AUTOSAR XML (schema 00046)
package /ComponentTypes
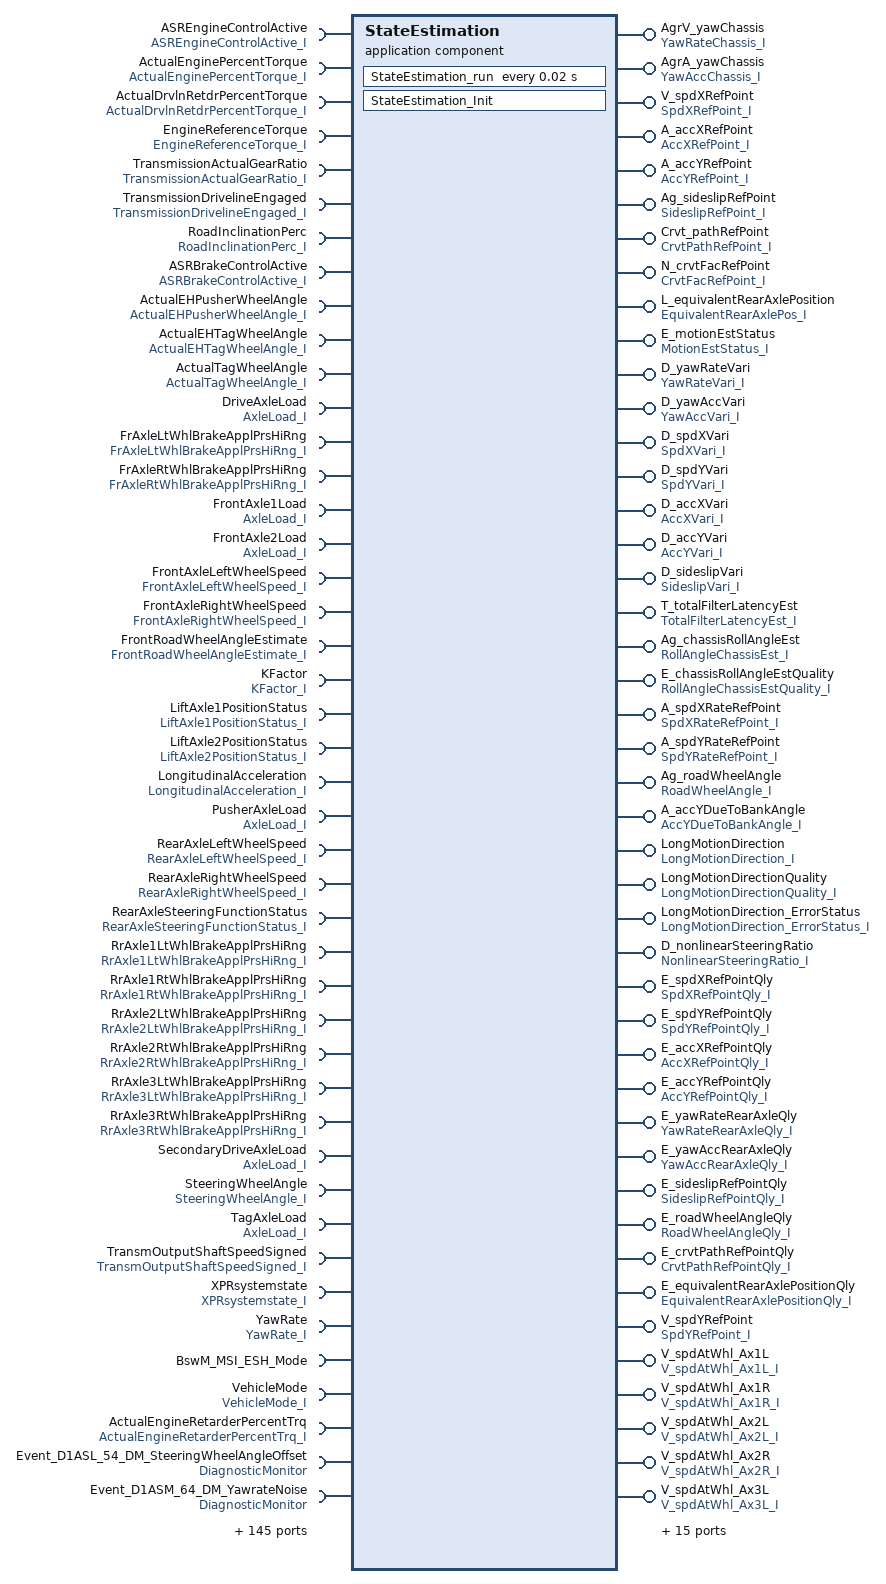
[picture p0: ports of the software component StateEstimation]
  application sw component type StateEstimation
    6 x require port:
      ASREngineControlActive: nonqueued-receiver-com-spec{data-element=ASREngineControlActive, alive-timeout=30, filter=data-filter-type=ALWAYS, init-value=constant-reference=C_ASREngineControlActive_IV}, required-interface=ASREngineControlActive_I
      ActualEnginePercentTorque: nonqueued-receiver-com-spec{data-element=ActualEnginePercentTorque, alive-timeout=30, init-value=constant-reference=C_ActualEnginePercentTorque_IV}, required-interface=ActualEnginePercentTorque_I
      ActualDrvlnRetdrPercentTorque: nonqueued-receiver-com-spec{data-element=ActualDrvlnRetdrPercentTorque, alive-timeout=30, init-value=constant-reference=C_ActualDrvlnRetdrPercentTorque_IV}, required-interface=ActualDrvlnRetdrPercentTorque_I
      EngineReferenceTorque: queued-receiver-com-spec{data-element=EngineReferenceTorque, queue-length=1}, required-interface=EngineReferenceTorque_I
      TransmissionActualGearRatio: nonqueued-receiver-com-spec{data-element=TransmissionActualGearRatio, alive-timeout=30, init-value=constant-reference=C_TransmissionActualGearRatio_IV}, required-interface=TransmissionActualGearRatio_I
      TransmissionDrivelineEngaged: nonqueued-receiver-com-spec{data-element=TransmissionDrivelineEngaged, alive-timeout=30, init-value=constant-reference=C_TransmissionDrivelineEngaged_IV}, required-interface=TransmissionDrivelineEngaged_I
    provide port AgrV_yawChassis: nonqueued-sender-com-spec=YawRateChassis, provided-interface=YawRateChassis_I
    provide port AgrA_yawChassis: nonqueued-sender-com-spec=YawAccChassis, provided-interface=YawAccChassis_I
    35 x require port:
      RoadInclinationPerc: nonqueued-receiver-com-spec{data-element=RoadInclinationPerc, alive-timeout=30, init-value=0}, required-interface=RoadInclinationPerc_I
      ASRBrakeControlActive: nonqueued-receiver-com-spec{data-element=ASRBrakeControlActive, alive-timeout=30, init-value=constant-reference=C_ASRBrakeControlActive_IV}, required-interface=ASRBrakeControlActive_I
      ActualEHPusherWheelAngle: nonqueued-receiver-com-spec{data-element=ActuaEHPusherWheelAngle, alive-timeout=30, filter=data-filter-type=ALWAYS, init-value=65535}, required-interface=ActualEHPusherWheelAngle_I
      ActualEHTagWheelAngle: nonqueued-receiver-com-spec{data-element=ActualEHTagWheelAngle, alive-timeout=30, filter=data-filter-type=ALWAYS, init-value=65535}, required-interface=ActualEHTagWheelAngle_I
      ActualTagWheelAngle: nonqueued-receiver-com-spec{data-element=ActualTagWheelAngle, alive-timeout=30, filter=data-filter-type=ALWAYS, init-value=constant-reference=C_ActualTagWheelAngle_IV}, required-interface=ActualTagWheelAngle_I
      DriveAxleLoad: nonqueued-receiver-com-spec{data-element=AxleLoad, alive-timeout=30, filter=data-filter-type=ALWAYS, init-value=constant-reference=C_DriveAxleLoad_IV}, required-interface=AxleLoad_I
      FrAxleLtWhlBrakeApplPrsHiRng: nonqueued-receiver-com-spec{data-element=FrAxleLtWhlBrakeApplPrsHiRng, alive-timeout=30, init-value=constant-reference=C_FrAxleLtWhlBrakeApplPrsHiRng_IV}, required-interface=FrAxleLtWhlBrakeApplPrsHiRng_I
      FrAxleRtWhlBrakeApplPrsHiRng: nonqueued-receiver-com-spec{data-element=FrAxleRtWhlBrakeApplPrsHiRng, alive-timeout=30, init-value=constant-reference=C_FrAxleRtWhlBrakeApplPrsHiRng_IV}, required-interface=FrAxleRtWhlBrakeApplPrsHiRng_I
      FrontAxle1Load: nonqueued-receiver-com-spec{data-element=AxleLoad, alive-timeout=30, filter=data-filter-type=ALWAYS, init-value=constant-reference=C_FrontAxle1Load_IV}, required-interface=AxleLoad_I
      FrontAxle2Load: nonqueued-receiver-com-spec{data-element=AxleLoad, alive-timeout=30, filter=data-filter-type=ALWAYS, init-value=constant-reference=C_FrontAxle2Load_IV}, required-interface=AxleLoad_I
      FrontAxleLeftWheelSpeed: nonqueued-receiver-com-spec{data-element=FrontAxleLeftWheelSpeed, alive-timeout=30, filter=data-filter-type=ALWAYS, init-value=constant-reference=C_FrontAxleLeftWheelSpeed_IV}, required-interface=FrontAxleLeftWheelSpeed_I
      FrontAxleRightWheelSpeed: nonqueued-receiver-com-spec{data-element=FrontAxleRightWheelSpeed, alive-timeout=30, filter=data-filter-type=ALWAYS, init-value=constant-reference=C_FrontAxleRightWheelSpeed_IV}, required-interface=FrontAxleRightWheelSpeed_I
      FrontRoadWheelAngleEstimate: nonqueued-receiver-com-spec{data-element=FrontRoadWheelAngleEstimate, alive-timeout=30, filter=data-filter-type=ALWAYS, init-value=constant-reference=C_FrontRoadWheelAngleEstimate_IV}, required-interface=FrontRoadWheelAngleEstimate_I
      KFactor: nonqueued-receiver-com-spec{data-element=KFactor, alive-timeout=30, init-value=constant-reference=C_kFactor_IV}, required-interface=KFactor_I
      LiftAxle1PositionStatus: nonqueued-receiver-com-spec{data-element=LiftAxle1PositionStatus, alive-timeout=30, filter=data-filter-type=ALWAYS, init-value=constant-reference=C_LiftAxle1PositionStatus_IV}, required-interface=LiftAxle1PositionStatus_I
      LiftAxle2PositionStatus: nonqueued-receiver-com-spec{data-element=LiftAxle2PositionStatus, alive-timeout=30, filter=data-filter-type=ALWAYS, init-value=constant-reference=C_LiftAxle2PositionStatus_IV}, required-interface=LiftAxle2PositionStatus_I
      LongitudinalAcceleration: nonqueued-receiver-com-spec{data-element=LongitudinalAcceleration, alive-timeout=30, filter=data-filter-type=ALWAYS, init-value=constant-reference=C_LongitudinalAcceleration_IV}, required-interface=LongitudinalAcceleration_I
      PusherAxleLoad: nonqueued-receiver-com-spec{data-element=AxleLoad, alive-timeout=30, filter=data-filter-type=ALWAYS, init-value=constant-reference=C_PusherAxleLoad_IV}, required-interface=AxleLoad_I
      RearAxleLeftWheelSpeed: nonqueued-receiver-com-spec{data-element=RearAxleLeftWheelSpeed, alive-timeout=30, filter=data-filter-type=ALWAYS, init-value=constant-reference=C_RearAxleLeftWheelSpeed_IV}, required-interface=RearAxleLeftWheelSpeed_I
      RearAxleRightWheelSpeed: nonqueued-receiver-com-spec{data-element=RearAxleRightWheelSpeed, alive-timeout=30, filter=data-filter-type=ALWAYS, init-value=constant-reference=C_RearAxleRightWheelSpeed_IV}, required-interface=RearAxleRightWheelSpeed_I
      RearAxleSteeringFunctionStatus: nonqueued-receiver-com-spec{data-element=RearAxleSteeringFunctionStatus, alive-timeout=30, filter=data-filter-type=ALWAYS, init-value=constant-reference=C_RearAxleSteeringFunctionStatus_IV}, required-interface=RearAxleSteeringFunctionStatus_I
      RrAxle1LtWhlBrakeApplPrsHiRng: nonqueued-receiver-com-spec{data-element=RrAxle1LtWhlBrakeApplPrsHiRng, alive-timeout=30, init-value=constant-reference=C_RrAxle1LtWhlBrakeApplPrsHiRng_IV}, required-interface=RrAxle1LtWhlBrakeApplPrsHiRng_I
      RrAxle1RtWhlBrakeApplPrsHiRng: nonqueued-receiver-com-spec{data-element=RrAxle1RtWhlBrakeApplPrsHiRng, alive-timeout=30, init-value=constant-reference=C_RrAxle1RtWhlBrakeApplPrsHiRng_IV}, required-interface=RrAxle1RtWhlBrakeApplPrsHiRng_I
      RrAxle2LtWhlBrakeApplPrsHiRng: nonqueued-receiver-com-spec{data-element=RrAxle2LtWhlBrakeApplPrsHiRng, alive-timeout=30, init-value=constant-reference=C_RrAxle2LtWhlBrakeApplPrsHiRng_IV}, required-interface=RrAxle2LtWhlBrakeApplPrsHiRng_I
      RrAxle2RtWhlBrakeApplPrsHiRng: nonqueued-receiver-com-spec{data-element=RrAxle2RtWhlBrakeApplPrsHiRng, alive-timeout=30, init-value=constant-reference=C_RrAxle2RtWhlBrakeApplPrsHiRng_IV}, required-interface=RrAxle2RtWhlBrakeApplPrsHiRng_I
      RrAxle3LtWhlBrakeApplPrsHiRng: nonqueued-receiver-com-spec{data-element=RrAxle3LtWhlBrakeApplPrsHiRng, alive-timeout=30, init-value=constant-reference=C_RrAxle3LtWhlBrakeApplPrsHiRng_IV}, required-interface=RrAxle3LtWhlBrakeApplPrsHiRng_I
      RrAxle3RtWhlBrakeApplPrsHiRng: nonqueued-receiver-com-spec{data-element=RrAxle3RtWhlBrakeApplPrsHiRng, alive-timeout=30, init-value=constant-reference=C_RrAxle3RtWhlBrakeApplPrsHiRng_IV}, required-interface=RrAxle3RtWhlBrakeApplPrsHiRng_I
      SecondaryDriveAxleLoad: nonqueued-receiver-com-spec{data-element=AxleLoad, alive-timeout=30, filter=data-filter-type=ALWAYS, init-value=constant-reference=C_SecondaryDriveAxleLoad_IV}, required-interface=AxleLoad_I
      SteeringWheelAngle: nonqueued-receiver-com-spec{data-element=SteeringWheelAngle, alive-timeout=30, filter=data-filter-type=ALWAYS, init-value=constant-reference=STEERING_WHEEL_ANGLE_INIT}, required-interface=SteeringWheelAngle_I
      TagAxleLoad: nonqueued-receiver-com-spec{data-element=AxleLoad, alive-timeout=30, filter=data-filter-type=ALWAYS, init-value=constant-reference=C_TagAxleLoad_IV}, required-interface=AxleLoad_I
      TransmOutputShaftSpeedSigned: nonqueued-receiver-com-spec{data-element=TransmOutputShaftSpeedSigned, alive-timeout=30, init-value=constant-reference=C_TransmOutputShaftSpeedSigned_IV}, required-interface=TransmOutputShaftSpeedSigned_I
      XPRsystemstate: nonqueued-receiver-com-spec{data-element=XPRsystemstate, alive-timeout=30, filter=data-filter-type=ALWAYS, init-value=constant-reference=C_XPRsystemstate_IV}, required-interface=XPRsystemstate_I
      YawRate: nonqueued-receiver-com-spec{data-element=YawRate, alive-timeout=30, filter=data-filter-type=ALWAYS, init-value=65535}, required-interface=YawRate_I
      BswM_MSI_ESH_Mode: mode-switch-receiver-com-spec=BswM_MDGP_ESH_Mode, required-interface=BswM_MSI_ESH_Mode
      VehicleMode: nonqueued-receiver-com-spec{data-element=VehicleMode, alive-timeout=30, init-value=constant-reference=C_VehicleMode_IV}, required-interface=VehicleMode_I
    57 x provide port:
      V_spdXRefPoint: nonqueued-sender-com-spec{data-element=SpdXRefPoint, init-value=fields=ElementConstant:0}, provided-interface=SpdXRefPoint_I
      A_accXRefPoint: nonqueued-sender-com-spec{data-element=AccXRefPoint, init-value=fields=ElementConstant:0}, provided-interface=AccXRefPoint_I
      A_accYRefPoint: nonqueued-sender-com-spec=AccYRefPoint, provided-interface=AccYRefPoint_I
      Ag_sideslipRefPoint: nonqueued-sender-com-spec=SideslipRefPoint, provided-interface=SideslipRefPoint_I
      Crvt_pathRefPoint: nonqueued-sender-com-spec=CrvtPathRefPoint, provided-interface=CrvtPathRefPoint_I
      N_crvtFacRefPoint: nonqueued-sender-com-spec=CrvtFacRefPoint, provided-interface=CrvtFacRefPoint_I
      L_equivalentRearAxlePosition: nonqueued-sender-com-spec=EquivalentRearAxlePos, provided-interface=EquivalentRearAxlePos_I
      E_motionEstStatus: nonqueued-sender-com-spec=MotionEstStatus, provided-interface=MotionEstStatus_I
      D_yawRateVari: nonqueued-sender-com-spec=YawRateVari, provided-interface=YawRateVari_I
      D_yawAccVari: nonqueued-sender-com-spec=YawAccVari, provided-interface=YawAccVari_I
      D_spdXVari: nonqueued-sender-com-spec=SpdXVari, provided-interface=SpdXVari_I
      D_spdYVari: nonqueued-sender-com-spec=SpdYVari, provided-interface=SpdYVari_I
      D_accXVari: nonqueued-sender-com-spec=AccXVari, provided-interface=AccXVari_I
      D_accYVari: nonqueued-sender-com-spec=AccYVari, provided-interface=AccYVari_I
      D_sideslipVari: nonqueued-sender-com-spec=SideslipVari, provided-interface=SideslipVari_I
      T_totalFilterLatencyEst: nonqueued-sender-com-spec=TotalFilterLatencyEst, provided-interface=TotalFilterLatencyEst_I
      Ag_chassisRollAngleEst: nonqueued-sender-com-spec=RollAngleChassisEst, provided-interface=RollAngleChassisEst_I
      E_chassisRollAngleEstQuality: nonqueued-sender-com-spec=RollAngleChassisEstQuality, provided-interface=RollAngleChassisEstQuality_I
      A_spdXRateRefPoint: nonqueued-sender-com-spec=SpdXRateRefPoint, provided-interface=SpdXRateRefPoint_I
      A_spdYRateRefPoint: nonqueued-sender-com-spec=SpdYRateRefPoint, provided-interface=SpdYRateRefPoint_I
      Ag_roadWheelAngle: nonqueued-sender-com-spec=RoadWheelAngle, provided-interface=RoadWheelAngle_I
      A_accYDueToBankAngle: nonqueued-sender-com-spec=AccYDueToBankAngle, provided-interface=AccYDueToBankAngle_I
      LongMotionDirection: nonqueued-sender-com-spec=LongMotionDirection, provided-interface=LongMotionDirection_I
      LongMotionDirectionQuality: nonqueued-sender-com-spec=LongMotionDirectionQuality, provided-interface=LongMotionDirectionQuality_I
      LongMotionDirection_ErrorStatus: nonqueued-sender-com-spec=LongMotionDirection_ErrorStatus, provided-interface=LongMotionDirection_ErrorStatus_I
      D_nonlinearSteeringRatio: nonqueued-sender-com-spec=NonlinearSteeringRatio, provided-interface=NonlinearSteeringRatio_I
      E_spdXRefPointQly: nonqueued-sender-com-spec=SpdXRefPointQly, provided-interface=SpdXRefPointQly_I
      E_spdYRefPointQly: nonqueued-sender-com-spec=SpdYRefPointQly, provided-interface=SpdYRefPointQly_I
      E_accXRefPointQly: nonqueued-sender-com-spec=AccXRefPointQly, provided-interface=AccXRefPointQly_I
      E_accYRefPointQly: nonqueued-sender-com-spec=AccYRefPointQly, provided-interface=AccYRefPointQly_I
      E_yawRateRearAxleQly: nonqueued-sender-com-spec=YawRateRearAxleQly, provided-interface=YawRateRearAxleQly_I
      E_yawAccRearAxleQly: nonqueued-sender-com-spec=YawAccRearAxleQly, provided-interface=YawAccRearAxleQly_I
      E_sideslipRefPointQly: nonqueued-sender-com-spec=SideslipRefPointQly, provided-interface=SideslipRefPointQly_I
      E_roadWheelAngleQly: nonqueued-sender-com-spec=RoadWheelAngleQly, provided-interface=RoadWheelAngleQly_I
      E_crvtPathRefPointQly: nonqueued-sender-com-spec=CrvtPathRefPointQly, provided-interface=CrvtPathRefPointQly_I
      E_equivalentRearAxlePositionQly: nonqueued-sender-com-spec=EquivalentRearAxlePositionQly, provided-interface=EquivalentRearAxlePositionQly_I
      V_spdYRefPoint: nonqueued-sender-com-spec{data-element=SpdYRefPoint, init-value=fields=ElementConstant:0}, provided-interface=SpdYRefPoint_I
      V_spdAtWhl_Ax1L: nonqueued-sender-com-spec=V_spdAtWhl_Ax1L, provided-interface=V_spdAtWhl_Ax1L_I
      V_spdAtWhl_Ax1R: nonqueued-sender-com-spec=V_spdAtWhl_Ax1R, provided-interface=V_spdAtWhl_Ax1R_I
      V_spdAtWhl_Ax2L: nonqueued-sender-com-spec=V_spdAtWhl_Ax2L, provided-interface=V_spdAtWhl_Ax2L_I
      V_spdAtWhl_Ax2R: nonqueued-sender-com-spec=V_spdAtWhl_Ax2R, provided-interface=V_spdAtWhl_Ax2R_I
      V_spdAtWhl_Ax3L: nonqueued-sender-com-spec=V_spdAtWhl_Ax3L, provided-interface=V_spdAtWhl_Ax3L_I
      V_spdAtWhl_Ax3R: nonqueued-sender-com-spec=V_spdAtWhl_Ax3R, provided-interface=V_spdAtWhl_Ax3R_I
      V_spdAtWhl_Ax4L: nonqueued-sender-com-spec=V_spdAtWhl_Ax4L, provided-interface=V_spdAtWhl_Ax4L_I
      V_spdAtWhl_Ax4R: nonqueued-sender-com-spec=V_spdAtWhl_Ax4R, provided-interface=V_spdAtWhl_Ax4R_I
      V_spdAtWhl_Ax5L: nonqueued-sender-com-spec=V_spdAtWhl_Ax5L, provided-interface=V_spdAtWhl_Ax5L_I
      V_spdAtWhl_Ax5R: nonqueued-sender-com-spec=V_spdAtWhl_Ax5R, provided-interface=V_spdAtWhl_Ax5R_I
      E_spdAtWhlQly_Ax1L: nonqueued-sender-com-spec=E_spdAtWhlQly_Ax1L, provided-interface=E_spdAtWhlQly_Ax1L_I
      E_spdAtWhlQly_Ax1R: nonqueued-sender-com-spec=E_spdAtWhlQly_Ax1R, provided-interface=E_spdAtWhlQly_Ax1R_I
      E_spdAtWhlQly_Ax2L: nonqueued-sender-com-spec=E_spdAtWhlQly_Ax2L, provided-interface=E_spdAtWhlQly_Ax2L_I
      E_spdAtWhlQly_Ax2R: nonqueued-sender-com-spec=E_spdAtWhlQly_Ax2R, provided-interface=E_spdAtWhlQly_Ax2R_I
      E_spdAtWhlQly_Ax3L: nonqueued-sender-com-spec=E_spdAtWhlQly_Ax3L, provided-interface=E_spdAtWhlQly_Ax3L_I
      E_spdAtWhlQly_Ax3R: nonqueued-sender-com-spec=E_spdAtWhlQly_Ax3R, provided-interface=E_spdAtWhlQly_Ax3R_I
      E_spdAtWhlQly_Ax4L: nonqueued-sender-com-spec=E_spdAtWhlQly_Ax4L, provided-interface=E_spdAtWhlQly_Ax4L_I
      E_spdAtWhlQly_Ax4R: nonqueued-sender-com-spec=E_spdAtWhlQly_Ax4R, provided-interface=E_spdAtWhlQly_Ax4R_I
      E_spdAtWhlQly_Ax5R: nonqueued-sender-com-spec=E_spdAtWhlQly_Ax5R, provided-interface=E_spdAtWhlQly_Ax5R_I
      E_spdAtWhlQly_Ax5L: nonqueued-sender-com-spec=E_spdAtWhlQly_Ax5L, provided-interface=E_spdAtWhlQly_Ax5L_I
    148 x require port:
      ActualEngineRetarderPercentTrq: nonqueued-receiver-com-spec{data-element=ActualEngineRetarderPercentTrq, alive-timeout=30, filter=data-filter-type=ALWAYS, init-value=constant-reference=C_ActualEngineRetarderPercentTrq_IV}, required-interface=ActualEngineRetarderPercentTrq_I
      Event_D1ASL_54_DM_SteeringWheelAngleOffset: required-interface=DiagnosticMonitor
        required-com-specs:
          SetEventStatus
          GetDTCOfEvent
          GetEventExtendedDataRecordEx
          GetEventFailed
          GetEventFreezeFrameDataEx
          GetEventStatus
          GetEventTested
          GetFaultDetectionCounter
          ResetEventStatus
          ResetEventDebounceStatus
          GetEventUdsStatus
      Event_D1ASM_64_DM_YawrateNoise: required-interface=DiagnosticMonitor
        required-com-specs:
          SetEventStatus
          GetDTCOfEvent
          GetEventExtendedDataRecordEx
          GetEventFailed
          GetEventFreezeFrameDataEx
          GetEventStatus
          GetEventTested
          GetFaultDetectionCounter
          ResetEventStatus
          ResetEventDebounceStatus
          GetEventUdsStatus
      P10VW_D_precLongAccMeas: parameter-require-com-spec{init-value=0, parameter=v}, required-interface=P10VW_D_precLongAccMeas
      P1AK9_SelfSteeredTagAxleThreshSpeed: parameter-require-com-spec{init-value=0, parameter=v}, required-interface=P1AK9_SelfSteeredTagAxleThreshSpeed
      X1C5B_D_lowSpdSnsrSelnLatAScaFac: parameter-require-com-spec{init-value=0, parameter=v}, required-interface=X1C5B_D_lowSpdSnsrSelnLatAScaFac
      X1C6U_D_FltHndlgIndirPrimSigFltScaFac: parameter-require-com-spec{init-value=0, parameter=v}, required-interface=X1C6U_D_FltHndlgIndirPrimSigFltScaFac
      P1A8I_ConfigAxle_4_axle_load_max: parameter-require-com-spec{init-value=0, parameter=v}, required-interface=P1A8I_ConfigAxle_4_axle_load_max
      P10VT_D_precYawJerkInput: parameter-require-com-spec{init-value=0, parameter=v}, required-interface=P10VT_D_precYawJerkInput
      P1A8A_ConfigAxle_4_p_thres: parameter-require-com-spec{init-value=0, parameter=v}, required-interface=P1A8A_ConfigAxle_4_p_thres
      X1C68_D_FltHndlgPrimSigFltScaFac: parameter-require-com-spec{init-value=0, parameter=v}, required-interface=X1C68_D_FltHndlgPrimSigFltScaFac
      P1A59_ConfigAxle_1_axle_type_liftable: parameter-require-com-spec{init-value=0, parameter=v}, required-interface=P1A59_ConfigAxle_1_axle_type_liftable
      P1A62_ConfigAxle_2_wh_rollingcircu: parameter-require-com-spec{init-value=0, parameter=v}, required-interface=P1A62_ConfigAxle_2_wh_rollingcircu
      P1A71_ConfigAxle_4_axle_type_steered: parameter-require-com-spec{init-value=0, parameter=v}, required-interface=P1A71_ConfigAxle_4_axle_type_steered
      X1C60_T_interventionNoTrustTime: parameter-require-com-spec{init-value=0, parameter=v}, required-interface=X1C60_T_interventionNoTrustTime
      P1BGV_SteeringRatio: parameter-require-com-spec{init-value=0, parameter=v}, required-interface=P1BGV_SteeringRatio
      P1L1L_VehicleType: parameter-require-com-spec{init-value=0, parameter=v}, required-interface=P1L1L_VehicleType
      P1A6U_ConfigAxle_2_axle_type_liftable: parameter-require-com-spec{init-value=0, parameter=v}, required-interface=P1A6U_ConfigAxle_2_axle_type_liftable
      P1A7N_ConfigAxle_3_wh_rollingcircu: parameter-require-com-spec{init-value=0, parameter=v}, required-interface=P1A7N_ConfigAxle_3_wh_rollingcircu
      X1C8Y_Tq_minEngineWheelTorque: parameter-require-com-spec{init-value=0, parameter=v}, required-interface=X1C8Y_Tq_minEngineWheelTorque
      X1C5E_D_lowSpdSnsrSelnWhlSpdScaFac: parameter-require-com-spec{init-value=0, parameter=v}, required-interface=X1C5E_D_lowSpdSnsrSelnWhlSpdScaFac
      P10WG_D_normSlipStfnAxle5: parameter-require-com-spec{init-value=0, parameter=v}, required-interface=P10WG_D_normSlipStfnAxle5
      X1DCK_T_absAsrTurnOffDly: parameter-require-com-spec{init-value=0, parameter=v}, required-interface=X1DCK_T_absAsrTurnOffDly
      P10W2_M_Axle5SuspVertLoads: parameter-require-com-spec{init-value=[0, 0], parameter=v}, required-interface=P10W2_M_Axle5SuspVertLoads
      P1A7C_ConfigAxle_2_axle_load_max: parameter-require-com-spec{init-value=0, parameter=v}, required-interface=P1A7C_ConfigAxle_2_axle_load_max
      P10WU_M_Axle1SuspVertLoads: parameter-require-com-spec{init-value=[0, 0], parameter=v}, required-interface=P10WU_M_Axle1SuspVertLoads
      P1A8L_ConfigAxle_5_axle_type_liftable: parameter-require-com-spec{init-value=0, parameter=v}, required-interface=P1A8L_ConfigAxle_5_axle_type_liftable
      X1C48_Frq_lowSpdSnsrSelnTqFilFrq: parameter-require-com-spec{init-value=0, parameter=v}, required-interface=X1C48_Frq_lowSpdSnsrSelnTqFilFrq
      P1A6J_ConfigAxle_1_p_thres: parameter-require-com-spec{init-value=0, parameter=v}, required-interface=P1A6J_ConfigAxle_1_p_thres
      P1A6R_ConfigAxle_1_axle_load_max: parameter-require-com-spec{init-value=0, parameter=v}, required-interface=P1A6R_ConfigAxle_1_axle_load_max
      P10WD_D_normSlipStfnAxle2: parameter-require-com-spec{init-value=0, parameter=v}, required-interface=P10WD_D_normSlipStfnAxle2
      P1A83_ConfigAxle_5_axle_load_max: parameter-require-com-spec{init-value=0, parameter=v}, required-interface=P1A83_ConfigAxle_5_axle_load_max
      P1KJ7_FAxleContactPatchOutside2OutsideDist: parameter-require-com-spec{init-value=0, parameter=v}, required-interface=P1KJ7_FAxleContactPatchOutside2OutsideDist
      P1CSG_RearAxleArrangement: parameter-require-com-spec{init-value=0, parameter=v}, required-interface=P1CSG_RearAxleArrangement
      P1A7Q_ConfigAxle_3_brake_factor: parameter-require-com-spec{init-value=0, parameter=v}, required-interface=P1A7Q_ConfigAxle_3_brake_factor
      X1DU3_T_absAsrRstDelayTime: parameter-require-com-spec{init-value=0, parameter=v}, required-interface=X1DU3_T_absAsrRstDelayTime
      P1B8U_VehicleTargetGeneratorSpeedLimits1: parameter-require-com-spec{init-value=0, parameter=v}, required-interface=P1B8U_VehicleTargetGeneratorSpeedLimits1
      X1BWH_YawRateMonitoringActivation: parameter-require-com-spec{init-value=0, parameter=v}, required-interface=X1BWH_YawRateMonitoringActivation
      P10W3_Stfn_Axle5SuspVertStfns: parameter-require-com-spec{init-value=[0, 0], parameter=v}, required-interface=P10W3_Stfn_Axle5SuspVertStfns
      X1C4J_B_enaSlipCmp: parameter-require-com-spec{init-value=0, parameter=v}, required-interface=X1C4J_B_enaSlipCmp
      P10WX_Stfn_Axle2SuspVertStfns: parameter-require-com-spec{init-value=[0, 0], parameter=v}, required-interface=P10WX_Stfn_Axle2SuspVertStfns
      X1C3K_D_precTrsmOutpShaftSpdMeas: parameter-require-com-spec{init-value=0, parameter=v}, required-interface=X1C3K_D_precTrsmOutpShaftSpdMeas
      P1A7F_ConfigAxle_3_axle_type_liftable: parameter-require-com-spec{init-value=0, parameter=v}, required-interface=P1A7F_ConfigAxle_3_axle_type_liftable
      P1A8M_ConfigAxle_5_axle_type_steered: parameter-require-com-spec{init-value=0, parameter=v}, required-interface=P1A8M_ConfigAxle_5_axle_type_steered
      X1C9S_V_mtnDetnThdSpd: parameter-require-com-spec{init-value=0, parameter=v}, required-interface=X1C9S_V_mtnDetnThdSpd
      X1DBJ_A_mtnDetnThdLongAcc: parameter-require-com-spec{init-value=0, parameter=v}, required-interface=X1DBJ_A_mtnDetnThdLongAcc
      X1C3E_D_precLongVelRateInit: parameter-require-com-spec{init-value=0, parameter=v}, required-interface=X1C3E_D_precLongVelRateInit
      P1AFC_BrandType: parameter-require-com-spec{init-value=0, parameter=v}, required-interface=P1AFC_BrandType
      X1C49_Frq_lowSpdSnsrSelnSpdFilFrq: parameter-require-com-spec{init-value=0, parameter=v}, required-interface=X1C49_Frq_lowSpdSnsrSelnSpdFilFrq
      P1BGZ_SteeringRatioRight2: parameter-require-com-spec{init-value=0, parameter=v}, required-interface=P1BGZ_SteeringRatioRight2
      X1DCG_B_enaAbsAsrDetn: parameter-require-com-spec{init-value=0, parameter=v}, required-interface=X1DCG_B_enaAbsAsrDetn
      P10V2_V_lowSpdSnsrSelnSpdThldUp: parameter-require-com-spec{init-value=0, parameter=v}, required-interface=P10V2_V_lowSpdSnsrSelnSpdThldUp
      P10WE_D_normSlipStfnAxle3: parameter-require-com-spec{init-value=0, parameter=v}, required-interface=P10WE_D_normSlipStfnAxle3
      P1CNH_DistRA1ToRA2: parameter-require-com-spec{init-value=0, parameter=v}, required-interface=P1CNH_DistRA1ToRA2
      X1C5C_D_lowSpdSnsrSelnYawRateScaFac: parameter-require-com-spec{init-value=0, parameter=v}, required-interface=X1C5C_D_lowSpdSnsrSelnYawRateScaFac
      X1C63_D_absTracCompLgtAScaFac: parameter-require-com-spec{init-value=0, parameter=v}, required-interface=X1C63_D_absTracCompLgtAScaFac
      P10VU_D_precLatJerkDueToBankAngleInput: parameter-require-com-spec{init-value=0, parameter=v}, required-interface=P10VU_D_precLatJerkDueToBankAngleInput
      X1C6V_D_FltHndlgIndirAltvSigFltScaFac: parameter-require-com-spec{init-value=0, parameter=v}, required-interface=X1C6V_D_FltHndlgIndirAltvSigFltScaFac
      P1A7B_ConfigAxle_2_axle_load_min: parameter-require-com-spec{init-value=0, parameter=v}, required-interface=P1A7B_ConfigAxle_2_axle_load_min
      P10W0_M_Axle4SuspVertLoads: parameter-require-com-spec{init-value=[0, 0], parameter=v}, required-interface=P10W0_M_Axle4SuspVertLoads
      X1C3A_L_trackWidthDrivenAxle: parameter-require-com-spec{init-value=0, parameter=v}, required-interface=X1C3A_L_trackWidthDrivenAxle
      P1A6A_ConfigAxle_1_axle_type_steered: parameter-require-com-spec{init-value=0, parameter=v}, required-interface=P1A6A_ConfigAxle_1_axle_type_steered
      P1A65_ConfigAxle_2_brake_factor: parameter-require-com-spec{init-value=0, parameter=v}, required-interface=P1A65_ConfigAxle_2_brake_factor
      X1C69_D_maxWheelSpeedTrustFac_vec: parameter-require-com-spec{init-value=5 x 0, parameter=v}, required-interface=X1C69_D_maxWheelSpeedTrustFac_vec
      X1C46_Tq_lowSpdSnsrSelnTqThldUp: parameter-require-com-spec{init-value=0, parameter=v}, required-interface=X1C46_Tq_lowSpdSnsrSelnTqThldUp
      P1A7W_ConfigAxle_3_axle_load_min: parameter-require-com-spec{init-value=0, parameter=v}, required-interface=P1A7W_ConfigAxle_3_axle_load_min
      P1BGW_SteeringRatioLeft1: parameter-require-com-spec{init-value=0, parameter=v}, required-interface=P1BGW_SteeringRatioLeft1
      X1C5P_D_precWhlSpdMeas: parameter-require-com-spec{init-value=0, parameter=v}, required-interface=X1C5P_D_precWhlSpdMeas
      P1A6V_ConfigAxle_2_axle_type_steered: parameter-require-com-spec{init-value=0, parameter=v}, required-interface=P1A6V_ConfigAxle_2_axle_type_steered
      X1C5W_T_zeroSpdFltrTurnOffDly: parameter-require-com-spec{init-value=0, parameter=v}, required-interface=X1C5W_T_zeroSpdFltrTurnOffDly
      X1C8Z_D_wheelSpeedTrustFac_vec: parameter-require-com-spec{init-value=5 x 0, parameter=v}, required-interface=X1C8Z_D_wheelSpeedTrustFac_vec
      P1CNJ_DistRA2ToRA3: parameter-require-com-spec{init-value=0, parameter=v}, required-interface=P1CNJ_DistRA2ToRA3
      P10WH_L_imuToFrontAxle: parameter-require-com-spec{init-value=0, parameter=v}, required-interface=P10WH_L_imuToFrontAxle
      P10W1_Stfn_Axle4SuspVertStfns: parameter-require-com-spec{init-value=[0, 0], parameter=v}, required-interface=P10W1_Stfn_Axle4SuspVertStfns
      P1A78_ConfigAxle_4_wh_rollingcircu: parameter-require-com-spec{init-value=0, parameter=v}, required-interface=P1A78_ConfigAxle_4_wh_rollingcircu
      P10WS_L_maxCogHeightFullyLaden: parameter-require-com-spec{init-value=0, parameter=v}, required-interface=P10WS_L_maxCogHeightFullyLaden
      P1K5K_E_EbsSwPackage: parameter-require-com-spec{init-value=0, parameter=v}, required-interface=P1K5K_E_EbsSwPackage
      X1C4U_B_enaLowSpdSnsrSeln: parameter-require-com-spec{init-value=0, parameter=v}, required-interface=X1C4U_B_enaLowSpdSnsrSeln
      P10WV_Stfn_Axle1SuspVertStfns: parameter-require-com-spec{init-value=[0, 0], parameter=v}, required-interface=P10WV_Stfn_Axle1SuspVertStfns
      X1C47_Tq_lowSpdSnsrSelnTqThldLo: parameter-require-com-spec{init-value=0, parameter=v}, required-interface=X1C47_Tq_lowSpdSnsrSelnTqThldLo
      P1A7X_ConfigAxle_3_axle_load_max: parameter-require-com-spec{init-value=0, parameter=v}, required-interface=P1A7X_ConfigAxle_3_axle_load_max
      P1A6K_ConfigAxle_1_brake_factor: parameter-require-com-spec{init-value=0, parameter=v}, required-interface=P1A6K_ConfigAxle_1_brake_factor
      X1DCF_T_mtnLowConfTolrTi: parameter-require-com-spec{init-value=0, parameter=v}, required-interface=X1DCF_T_mtnLowConfTolrTi
      P1A6Q_ConfigAxle_1_axle_load_min: parameter-require-com-spec{init-value=0, parameter=v}, required-interface=P1A6Q_ConfigAxle_1_axle_load_min
      P1CSH_FrontAxleArrangement: parameter-require-com-spec{init-value=0, parameter=v}, required-interface=P1CSH_FrontAxleArrangement
      P1A82_ConfigAxle_5_axle_load_min: parameter-require-com-spec{init-value=0, parameter=v}, required-interface=P1A82_ConfigAxle_5_axle_load_min
      X1DBH_D_precLatAccDueToBankAngleInit: parameter-require-com-spec{init-value=0, parameter=v}, required-interface=X1DBH_D_precLatAccDueToBankAngleInit
      P10VX_D_precLatAccMeas: parameter-require-com-spec{init-value=0, parameter=v}, required-interface=P10VX_D_precLatAccMeas
      X1C6T_D_FltHndlgAltvSigFltScaFac: parameter-require-com-spec{init-value=0, parameter=v}, required-interface=X1C6T_D_FltHndlgAltvSigFltScaFac
      P11DU_E_BusAxleType: parameter-require-com-spec{init-value=0, parameter=v}, required-interface=P11DU_E_BusAxleType
      P1B8V_VehicleTargetGeneratorSpeedLimits2: parameter-require-com-spec{init-value=0, parameter=v}, required-interface=P1B8V_VehicleTargetGeneratorSpeedLimits2
      X1DBQ_D_absTracCompLongJerkScaFac: parameter-require-com-spec{init-value=0, parameter=v}, required-interface=X1DBQ_D_absTracCompLongJerkScaFac
      X1C5A_D_lowSpdSnsrSelnLgtAScaFac: parameter-require-com-spec{init-value=0, parameter=v}, required-interface=X1C5A_D_lowSpdSnsrSelnLgtAScaFac
      X1C61_T_interventionRampUpTime: parameter-require-com-spec{init-value=0, parameter=v}, required-interface=X1C61_T_interventionRampUpTime
      P10VS_D_precLongJerkInput: parameter-require-com-spec{init-value=0, parameter=v}, required-interface=P10VS_D_precLongJerkInput
      P1A8H_ConfigAxle_4_axle_load_min: parameter-require-com-spec{init-value=0, parameter=v}, required-interface=P1A8H_ConfigAxle_4_axle_load_min
      P1KME_DistFA1ToFA2: parameter-require-com-spec{init-value=0, parameter=v}, required-interface=P1KME_DistFA1ToFA2
      X1DBO_D_absTracCompLatAScaFac: parameter-require-com-spec{init-value=0, parameter=v}, required-interface=X1DBO_D_absTracCompLatAScaFac
      X1C5T_D_lowSpdSnsrSelnLgtJerkScaFacSpd: parameter-require-com-spec{init-value=0, parameter=v}, required-interface=X1C5T_D_lowSpdSnsrSelnLgtJerkScaFacSpd
      P10WY_M_Axle3SuspVertLoads: parameter-require-com-spec{init-value=[0, 0], parameter=v}, required-interface=P10WY_M_Axle3SuspVertLoads
      P1A8B_ConfigAxle_4_brake_factor: parameter-require-com-spec{init-value=0, parameter=v}, required-interface=P1A8B_ConfigAxle_4_brake_factor
      X1C8W_B_enaWheelDeselection: parameter-require-com-spec{init-value=0, parameter=v}, required-interface=X1C8W_B_enaWheelDeselection
      X1DU0_T_absAsrDetnDelayTime: parameter-require-com-spec{init-value=0, parameter=v}, required-interface=X1DU0_T_absAsrDetnDelayTime
      P1A7G_ConfigAxle_3_axle_type_steered: parameter-require-com-spec{init-value=0, parameter=v}, required-interface=P1A7G_ConfigAxle_3_axle_type_steered
      X1C3F_D_precYawRateInit: parameter-require-com-spec{init-value=0, parameter=v}, required-interface=X1C3F_D_precYawRateInit
      P1A6H_ConfigAxle_1_wh_rollingcircu: parameter-require-com-spec{init-value=0, parameter=v}, required-interface=P1A6H_ConfigAxle_1_wh_rollingcircu
      P1A70_ConfigAxle_4_axle_type_liftable: parameter-require-com-spec{init-value=0, parameter=v}, required-interface=P1A70_ConfigAxle_4_axle_type_liftable
      X1DCH_A_whlRateAbsAsrDetnThd: parameter-require-com-spec{init-value=0, parameter=v}, required-interface=X1DCH_A_whlRateAbsAsrDetnThd
      P1A8V_ConfigAxle_5_p_thres: parameter-require-com-spec{init-value=0, parameter=v}, required-interface=P1A8V_ConfigAxle_5_p_thres
      P1A7P_ConfigAxle_3_p_thres: parameter-require-com-spec{init-value=0, parameter=v}, required-interface=P1A7P_ConfigAxle_3_p_thres
      P1RPH_NetworkArchitecture: parameter-require-com-spec{init-value=0, parameter=v}, required-interface=P1RPH_NetworkArchitecture
      P10VY_D_precYawRateMeas: parameter-require-com-spec{init-value=0, parameter=v}, required-interface=P10VY_D_precYawRateMeas
      X1C5D_D_lowSpdSnsrSelnTrsmSpdScaFac: parameter-require-com-spec{init-value=0, parameter=v}, required-interface=X1C5D_D_lowSpdSnsrSelnTrsmSpdScaFac
      P1CSI_TagAxleFeatures: parameter-require-com-spec{init-value=0, parameter=v}, required-interface=P1CSI_TagAxleFeatures
      P10WF_D_normSlipStfnAxle4: parameter-require-com-spec{init-value=0, parameter=v}, required-interface=P10WF_D_normSlipStfnAxle4
      X1C62_B_enaTracComp: parameter-require-com-spec{init-value=0, parameter=v}, required-interface=X1C62_B_enaTracComp
      X1DBP_D_absTracCompYawRateScaFac: parameter-require-com-spec{init-value=0, parameter=v}, required-interface=X1DBP_D_absTracCompYawRateScaFac
      X1C7C_V_maxWheelSpeedTrustBreakPoints_vec: parameter-require-com-spec{init-value=5 x 0, parameter=v}, required-interface=X1C7C_V_maxWheelSpeedTrustBreakPoints_vec
      X1C5U_Frq_lowSpdSnsrSelnSpdFilFrq: parameter-require-com-spec{init-value=0, parameter=v}, required-interface=X1C5U_Frq_lowSpdSnsrSelnSpdFilFrq
      P10WZ_Stfn_Axle3SuspVertStfns: parameter-require-com-spec{init-value=[0, 0], parameter=v}, required-interface=P10WZ_Stfn_Axle3SuspVertStfns
      X1C29_L_trackWidthNonDrivenAxle: parameter-require-com-spec{init-value=0, parameter=v}, required-interface=X1C29_L_trackWidthNonDrivenAxle
      X1C8X_Tq_minTotalBrakeTorque: parameter-require-com-spec{init-value=0, parameter=v}, required-interface=X1C8X_Tq_minTotalBrakeTorque
      X1C3G_D_precYawAccInit: parameter-require-com-spec{init-value=0, parameter=v}, required-interface=X1C3G_D_precYawAccInit
      P1A64_ConfigAxle_2_p_thres: parameter-require-com-spec{init-value=0, parameter=v}, required-interface=P1A64_ConfigAxle_2_p_thres
      P1E5Z_Radar2FrontAxleDist: parameter-require-com-spec{init-value=0, parameter=v}, required-interface=P1E5Z_Radar2FrontAxleDist
      P1A8W_ConfigAxle_5_brake_factor: parameter-require-com-spec{init-value=0, parameter=v}, required-interface=P1A8W_ConfigAxle_5_brake_factor
      P10WC_D_normSlipStfnAxle1: parameter-require-com-spec{init-value=0, parameter=v}, required-interface=P10WC_D_normSlipStfnAxle1
      X1DCI_Frq_whlRateFilFrq: parameter-require-com-spec{init-value=0, parameter=v}, required-interface=X1DCI_Frq_whlRateFilFrq
      X1C5Q_D_lowSpdSnsrSelnLgtJerkScaFacTrq: parameter-require-com-spec{init-value=0, parameter=v}, required-interface=X1C5Q_D_lowSpdSnsrSelnLgtJerkScaFacTrq
      P10WR_L_minCogHeightUnladen: parameter-require-com-spec{init-value=0, parameter=v}, required-interface=P10WR_L_minCogHeightUnladen
      X1C80_V_speedDifferenceBreakPoints_vec: parameter-require-com-spec{init-value=5 x 0, parameter=v}, required-interface=X1C80_V_speedDifferenceBreakPoints_vec
      P1IJ3_EquivalentWheelbaseTurning: parameter-require-com-spec{init-value=0, parameter=v}, required-interface=P1IJ3_EquivalentWheelbaseTurning
      X1DCM_A_whlRateAbsAsrRstThd: parameter-require-com-spec{init-value=0, parameter=v}, required-interface=X1DCM_A_whlRateAbsAsrRstThd
      X1C3D_D_precLongVelInit: parameter-require-com-spec{init-value=0, parameter=v}, required-interface=X1C3D_D_precLongVelInit
      P1AT2_SelfSteeredTagAxleSpeedHysteresis: parameter-require-com-spec{init-value=0, parameter=v}, required-interface=P1AT2_SelfSteeredTagAxleSpeedHysteresis
      P10WT_AgV_maxPitchRate: parameter-require-com-spec{init-value=0, parameter=v}, required-interface=P10WT_AgV_maxPitchRate
      P10WW_M_Axle2SuspVertLoads: parameter-require-com-spec{init-value=[0, 0], parameter=v}, required-interface=P10WW_M_Axle2SuspVertLoads
      P1BGX_SteeringRatioLeft2: parameter-require-com-spec{init-value=0, parameter=v}, required-interface=P1BGX_SteeringRatioLeft2
      X1C9T_V_mtnDetnHysSpd: parameter-require-com-spec{init-value=0, parameter=v}, required-interface=X1C9T_V_mtnDetnHysSpd
      X1C6Z_B_enaAbsComp: parameter-require-com-spec{init-value=0, parameter=v}, required-interface=X1C6Z_B_enaAbsComp
      P1BGY_SteeringRatioRight1: parameter-require-com-spec{init-value=0, parameter=v}, required-interface=P1BGY_SteeringRatioRight1
      P10V1_V_lowSpdSnsrSelnSpdThldLo: parameter-require-com-spec{init-value=0, parameter=v}, required-interface=P10V1_V_lowSpdSnsrSelnSpdThldLo
      P1A8T_ConfigAxle_5_wh_rollingcircu: parameter-require-com-spec{init-value=0, parameter=v}, required-interface=P1A8T_ConfigAxle_5_wh_rollingcircu
      P1A0N_B_EspNotAvailable: parameter-require-com-spec{init-value=0, parameter=v}, required-interface=P1A0N_B_EspNotAvailable
      P1AZQ_WheelBase: parameter-require-com-spec{init-value=0, parameter=v}, required-interface=P1AZQ_WheelBase
      P1E50_VehicleWidth_mm: parameter-require-com-spec{init-value=0, parameter=v}, required-interface=P1E50_VehicleWidth_mm
      P1M6I_NoOfPulsesPerRevolution: parameter-require-com-spec{init-value=0, parameter=v}, required-interface=P1M6I_NoOfPulsesPerRevolution
      P1C54_FactoryModeActive: parameter-require-com-spec{init-value=0, parameter=v}, required-interface=P1C54_FactoryModeActive
    behavior StateEstimation_InternalBehavior: data-type-mapping=StateEstimation_TypeMappingSet, port-api-option{enable-take-address=false, indirect-api=false, port=Event_D1ASL_54_DM_SteeringWheelAngleOffset}
      timing event TMT_StateEstimation_run: start-on-event=StateEstimation_run, period=0.02
        disabled-mode:
          BswM_MSI_ESH_Mode.BswM_MDGP_ESH_Mode.WAKEUP
          BswM_MSI_ESH_Mode.BswM_MDGP_ESH_Mode.SHUTDOWN
          BswM_MSI_ESH_Mode.BswM_MDGP_ESH_Mode.POSTRUN
          BswM_MSI_ESH_Mode.BswM_MDGP_ESH_Mode.STARTUP
      swc mode switch event MST_StateEstimation_Init_0: start-on-event=StateEstimation_Init, activation=ON-ENTRY, mode=BswM_MSI_ESH_Mode.BswM_MDGP_ESH_Mode.RUN
      runnable StateEstimation_Init
      runnable StateEstimation_run
        data-receive-point-by-arguments:
          41 x access:
            REC_ASRBrakeControlActive_ASRBrakeControlActive: accessed-variable=ASRBrakeControlActive.ASRBrakeControlActive
            REC_ASREngineControlActive_ASREngineControlActive: accessed-variable=ASREngineControlActive.ASREngineControlActive
            REC_ActualDrvlnRetdrPercentTorque_ActualDrvlnRetdrPercentTorque: accessed-variable=ActualDrvlnRetdrPercentTorque.ActualDrvlnRetdrPercentTorque
            REC_ActualEHPusherWheelAngle_ActuaEHPusherWheelAngle: accessed-variable=ActualEHPusherWheelAngle.ActuaEHPusherWheelAngle
            REC_ActualEHTagWheelAngle_ActualEHTagWheelAngle: accessed-variable=ActualEHTagWheelAngle.ActualEHTagWheelAngle
            REC_ActualEnginePercentTorque_ActualEnginePercentTorque: accessed-variable=ActualEnginePercentTorque.ActualEnginePercentTorque
            REC_ActualTagWheelAngle_ActualTagWheelAngle: accessed-variable=ActualTagWheelAngle.ActualTagWheelAngle
            REC_DriveAxleLoad_AxleLoad: accessed-variable=DriveAxleLoad.AxleLoad
            REC_EngineReferenceTorque_EngineReferenceTorque: accessed-variable=EngineReferenceTorque.EngineReferenceTorque
            REC_FrAxleLtWhlBrakeApplPrsHiRng_FrAxleLtWhlBrakeApplPrsHiRng: accessed-variable=FrAxleLtWhlBrakeApplPrsHiRng.FrAxleLtWhlBrakeApplPrsHiRng
            REC_FrAxleRtWhlBrakeApplPrsHiRng_FrAxleRtWhlBrakeApplPrsHiRng: accessed-variable=FrAxleRtWhlBrakeApplPrsHiRng.FrAxleRtWhlBrakeApplPrsHiRng
            REC_FrontAxle1Load_AxleLoad: accessed-variable=FrontAxle1Load.AxleLoad
            REC_FrontAxle2Load_AxleLoad: accessed-variable=FrontAxle2Load.AxleLoad
            REC_FrontAxleLeftWheelSpeed_FrontAxleLeftWheelSpeed: accessed-variable=FrontAxleLeftWheelSpeed.FrontAxleLeftWheelSpeed
            REC_FrontAxleRightWheelSpeed_FrontAxleRightWheelSpeed: accessed-variable=FrontAxleRightWheelSpeed.FrontAxleRightWheelSpeed
            REC_FrontRoadWheelAngleEstimate_FrontRoadWheelAngleEstimate: accessed-variable=FrontRoadWheelAngleEstimate.FrontRoadWheelAngleEstimate
            REC_KFactor_KFactor: accessed-variable=KFactor.KFactor
            REC_LiftAxle1PositionStatus_LiftAxle1PositionStatus: accessed-variable=LiftAxle1PositionStatus.LiftAxle1PositionStatus
            REC_LiftAxle2PositionStatus_LiftAxle2PositionStatus: accessed-variable=LiftAxle2PositionStatus.LiftAxle2PositionStatus
            REC_LongitudinalAcceleration_LongitudinalAcceleration: accessed-variable=LongitudinalAcceleration.LongitudinalAcceleration
            REC_PusherAxleLoad_AxleLoad: accessed-variable=PusherAxleLoad.AxleLoad
            REC_RearAxleLeftWheelSpeed_RearAxleLeftWheelSpeed: accessed-variable=RearAxleLeftWheelSpeed.RearAxleLeftWheelSpeed
            REC_RearAxleRightWheelSpeed_RearAxleRightWheelSpeed: accessed-variable=RearAxleRightWheelSpeed.RearAxleRightWheelSpeed
            REC_RearAxleSteeringFunctionStatus_RearAxleSteeringFunctionStatus: accessed-variable=RearAxleSteeringFunctionStatus.RearAxleSteeringFunctionStatus
            REC_RoadInclinationPerc_RoadInclinationPerc: accessed-variable=RoadInclinationPerc.RoadInclinationPerc
            REC_RrAxle1LtWhlBrakeApplPrsHiRng_RrAxle1LtWhlBrakeApplPrsHiRng: accessed-variable=RrAxle1LtWhlBrakeApplPrsHiRng.RrAxle1LtWhlBrakeApplPrsHiRng
            REC_RrAxle1RtWhlBrakeApplPrsHiRng_RrAxle1RtWhlBrakeApplPrsHiRng: accessed-variable=RrAxle1RtWhlBrakeApplPrsHiRng.RrAxle1RtWhlBrakeApplPrsHiRng
            REC_RrAxle2LtWhlBrakeApplPrsHiRng_RrAxle2LtWhlBrakeApplPrsHiRng: accessed-variable=RrAxle2LtWhlBrakeApplPrsHiRng.RrAxle2LtWhlBrakeApplPrsHiRng
            REC_RrAxle2RtWhlBrakeApplPrsHiRng_RrAxle2RtWhlBrakeApplPrsHiRng: accessed-variable=RrAxle2RtWhlBrakeApplPrsHiRng.RrAxle2RtWhlBrakeApplPrsHiRng
            REC_RrAxle3LtWhlBrakeApplPrsHiRng_RrAxle3LtWhlBrakeApplPrsHiRng: accessed-variable=RrAxle3LtWhlBrakeApplPrsHiRng.RrAxle3LtWhlBrakeApplPrsHiRng
            REC_RrAxle3RtWhlBrakeApplPrsHiRng_RrAxle3RtWhlBrakeApplPrsHiRng: accessed-variable=RrAxle3RtWhlBrakeApplPrsHiRng.RrAxle3RtWhlBrakeApplPrsHiRng
            REC_SecondaryDriveAxleLoad_AxleLoad: accessed-variable=SecondaryDriveAxleLoad.AxleLoad
            REC_SteeringWheelAngle_SteeringWheelAngle: accessed-variable=SteeringWheelAngle.SteeringWheelAngle
            REC_TagAxleLoad_AxleLoad: accessed-variable=TagAxleLoad.AxleLoad
            REC_TransmOutputShaftSpeedSigned_TransmOutputShaftSpeedSigned: accessed-variable=TransmOutputShaftSpeedSigned.TransmOutputShaftSpeedSigned
            REC_TransmissionActualGearRatio_TransmissionActualGearRatio: accessed-variable=TransmissionActualGearRatio.TransmissionActualGearRatio
            REC_TransmissionDrivelineEngaged_TransmissionDrivelineEngaged: accessed-variable=TransmissionDrivelineEngaged.TransmissionDrivelineEngaged
            REC_XPRsystemstate_XPRsystemstate: accessed-variable=XPRsystemstate.XPRsystemstate
            REC_YawRate_YawRate: accessed-variable=YawRate.YawRate
            REC_VehicleMode_VehicleMode: accessed-variable=VehicleMode.VehicleMode
            REC_ActualEngineRetarderPercentTrq_ActualEngineRetarderPercentTrq: accessed-variable=ActualEngineRetarderPercentTrq.ActualEngineRetarderPercentTrq
        data-send-points:
          59 x access:
            SEND_A_accXRefPoint_Element: accessed-variable=A_accXRefPoint.AccXRefPoint
            SEND_A_accYDueToBankAngle_Element: accessed-variable=A_accYDueToBankAngle.AccYDueToBankAngle
            SEND_A_accYRefPoint_Element: accessed-variable=A_accYRefPoint.AccYRefPoint
            SEND_A_spdXRateRefPoint_Element: accessed-variable=A_spdXRateRefPoint.SpdXRateRefPoint
            SEND_A_spdYRateRefPoint_Element: accessed-variable=A_spdYRateRefPoint.SpdYRateRefPoint
            SEND_Ag_chassisRollAngleEst_Element: accessed-variable=Ag_chassisRollAngleEst.RollAngleChassisEst
            SEND_Ag_roadWheelAngle_Element: accessed-variable=Ag_roadWheelAngle.RoadWheelAngle
            SEND_Ag_sideslipRefPoint_Element: accessed-variable=Ag_sideslipRefPoint.SideslipRefPoint
            SEND_AgrA_yawChassis_Element: accessed-variable=AgrA_yawChassis.YawAccChassis
            SEND_AgrV_yawChassis_Element: accessed-variable=AgrV_yawChassis.YawRateChassis
            SEND_Crvt_pathRefPoint_Element: accessed-variable=Crvt_pathRefPoint.CrvtPathRefPoint
            SEND_D_accXVari_Element: accessed-variable=D_accXVari.AccXVari
            SEND_D_accYVari_Element: accessed-variable=D_accYVari.AccYVari
            SEND_D_nonlinearSteeringRatio_Element: accessed-variable=D_nonlinearSteeringRatio.NonlinearSteeringRatio
            SEND_D_sideslipVari_Element: accessed-variable=D_sideslipVari.SideslipVari
            SEND_D_spdXVari_Element: accessed-variable=D_spdXVari.SpdXVari
            SEND_D_spdYVari_Element: accessed-variable=D_spdYVari.SpdYVari
            SEND_D_yawAccVari_Element: accessed-variable=D_yawAccVari.YawAccVari
            SEND_D_yawRateVari_Element: accessed-variable=D_yawRateVari.YawRateVari
            SEND_E_accXRefPointQly_Element: accessed-variable=E_accXRefPointQly.AccXRefPointQly
            SEND_E_accYRefPointQly_Element: accessed-variable=E_accYRefPointQly.AccYRefPointQly
            SEND_E_chassisRollAngleEstQuality_Element: accessed-variable=E_chassisRollAngleEstQuality.RollAngleChassisEstQuality
            SEND_E_crvtPathRefPointQly_Element: accessed-variable=E_crvtPathRefPointQly.CrvtPathRefPointQly
            SEND_E_equivalentRearAxlePositionQly_Element: accessed-variable=E_equivalentRearAxlePositionQly.EquivalentRearAxlePositionQly
            SEND_E_motionEstStatus_Element: accessed-variable=E_motionEstStatus.MotionEstStatus
            SEND_E_roadWheelAngleQly_Element: accessed-variable=E_roadWheelAngleQly.RoadWheelAngleQly
            SEND_E_sideslipRefPointQly_Element: accessed-variable=E_sideslipRefPointQly.SideslipRefPointQly
            SEND_E_spdXRefPointQly_Element: accessed-variable=E_spdXRefPointQly.SpdXRefPointQly
            SEND_E_spdYRefPointQly_Element: accessed-variable=E_spdYRefPointQly.SpdYRefPointQly
            SEND_E_yawAccRearAxleQly_Element: accessed-variable=E_yawAccRearAxleQly.YawAccRearAxleQly
            SEND_E_yawRateRearAxleQly_Element: accessed-variable=E_yawRateRearAxleQly.YawRateRearAxleQly
            SEND_L_equivalentRearAxlePosition_Element: accessed-variable=L_equivalentRearAxlePosition.EquivalentRearAxlePos
            SEND_LongMotionDirection_Element: accessed-variable=LongMotionDirection.LongMotionDirection
            SEND_LongMotionDirectionQuality_Element: accessed-variable=LongMotionDirectionQuality.LongMotionDirectionQuality
            SEND_LongMotionDirection_ErrorStatus_Element: accessed-variable=LongMotionDirection_ErrorStatus.LongMotionDirection_ErrorStatus
            SEND_N_crvtFacRefPoint_Element: accessed-variable=N_crvtFacRefPoint.CrvtFacRefPoint
            SEND_T_totalFilterLatencyEst_Element: accessed-variable=T_totalFilterLatencyEst.TotalFilterLatencyEst
            SEND_V_spdXRefPoint_Element: accessed-variable=V_spdXRefPoint.SpdXRefPoint
            SEND_V_spdYRefPoint_Element: accessed-variable=V_spdYRefPoint.SpdYRefPoint
            SEND_E_spdAtWhlQly_Ax1L_E_spdAtWhlQly_Ax1L: accessed-variable=E_spdAtWhlQly_Ax1L.E_spdAtWhlQly_Ax1L
            SEND_E_spdAtWhlQly_Ax1R_E_spdAtWhlQly_Ax1R: accessed-variable=E_spdAtWhlQly_Ax1R.E_spdAtWhlQly_Ax1R
            SEND_E_spdAtWhlQly_Ax2L_E_spdAtWhlQly_Ax2L: accessed-variable=E_spdAtWhlQly_Ax2L.E_spdAtWhlQly_Ax2L
            SEND_E_spdAtWhlQly_Ax2R_E_spdAtWhlQly_Ax2R: accessed-variable=E_spdAtWhlQly_Ax2R.E_spdAtWhlQly_Ax2R
            SEND_E_spdAtWhlQly_Ax3L_E_spdAtWhlQly_Ax3L: accessed-variable=E_spdAtWhlQly_Ax3L.E_spdAtWhlQly_Ax3L
            SEND_E_spdAtWhlQly_Ax3R_E_spdAtWhlQly_Ax3R: accessed-variable=E_spdAtWhlQly_Ax3R.E_spdAtWhlQly_Ax3R
            SEND_E_spdAtWhlQly_Ax4L_E_spdAtWhlQly_Ax4L: accessed-variable=E_spdAtWhlQly_Ax4L.E_spdAtWhlQly_Ax4L
            SEND_E_spdAtWhlQly_Ax4R_E_spdAtWhlQly_Ax4R: accessed-variable=E_spdAtWhlQly_Ax4R.E_spdAtWhlQly_Ax4R
            SEND_E_spdAtWhlQly_Ax5L_E_spdAtWhlQly_Ax5L: accessed-variable=E_spdAtWhlQly_Ax5L.E_spdAtWhlQly_Ax5L
            SEND_E_spdAtWhlQly_Ax5R_E_spdAtWhlQly_Ax5R: accessed-variable=E_spdAtWhlQly_Ax5R.E_spdAtWhlQly_Ax5R
            SEND_V_spdAtWhl_Ax1L_V_spdAtWhl_Ax1L: accessed-variable=V_spdAtWhl_Ax1L.V_spdAtWhl_Ax1L
            SEND_V_spdAtWhl_Ax1R_V_spdAtWhl_Ax1R: accessed-variable=V_spdAtWhl_Ax1R.V_spdAtWhl_Ax1R
            SEND_V_spdAtWhl_Ax2L_V_spdAtWhl_Ax2L: accessed-variable=V_spdAtWhl_Ax2L.V_spdAtWhl_Ax2L
            SEND_V_spdAtWhl_Ax2R_V_spdAtWhl_Ax2R: accessed-variable=V_spdAtWhl_Ax2R.V_spdAtWhl_Ax2R
            SEND_V_spdAtWhl_Ax3L_V_spdAtWhl_Ax3L: accessed-variable=V_spdAtWhl_Ax3L.V_spdAtWhl_Ax3L
            SEND_V_spdAtWhl_Ax3R_V_spdAtWhl_Ax3R: accessed-variable=V_spdAtWhl_Ax3R.V_spdAtWhl_Ax3R
            SEND_V_spdAtWhl_Ax4L_V_spdAtWhl_Ax4L: accessed-variable=V_spdAtWhl_Ax4L.V_spdAtWhl_Ax4L
            SEND_V_spdAtWhl_Ax4R_V_spdAtWhl_Ax4R: accessed-variable=V_spdAtWhl_Ax4R.V_spdAtWhl_Ax4R
            SEND_V_spdAtWhl_Ax5L_V_spdAtWhl_Ax5L: accessed-variable=V_spdAtWhl_Ax5L.V_spdAtWhl_Ax5L
            SEND_V_spdAtWhl_Ax5R_V_spdAtWhl_Ax5R: accessed-variable=V_spdAtWhl_Ax5R.V_spdAtWhl_Ax5R
  swc implementation StateEstimation_Implementation: behavior=StateEstimation_InternalBehavior
